# STM32F030x6 register map
File version: 1.0
Registers are 32-bit, read-write, reset 0x0 unless marked. A register's access mark holds for its fields unless they carry their own. Offsets are from the block's base; [hi:lo] are bit positions; {n}, {i} and the like mark numbered series.

## PWR — Power Control
Base 0x40007000
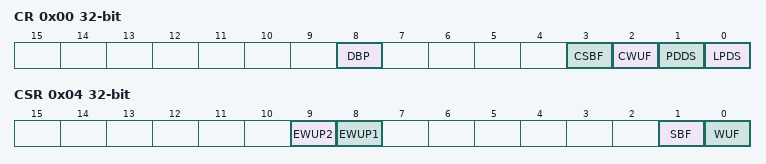
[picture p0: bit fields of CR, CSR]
0x00 CR — PWR power control register
  [8] DBP — Disable Backup Domain write protection
  [3] CSBF — Clear Standby Flag
  [2] CWUF — Clear Wakeup Flag
  [1] PDDS — Power Down Deepsleep
  [0] LPDS — Low-power Deepsleep
    0=MAIN (Voltage Regulator in main mode during deepsleep mode); 1=LOW_POWER (Voltage Regulator in low-power mode during deepsleep mode)
0x04 CSR — PWR power control/status register
  [9] EWUP2 — Enable WKUP pin 2
  [8] EWUP1 — Enable WKUP pin 1
  [1] SBF — Standby Flag
  [0] WUF — Wakeup Flag

## SYSCFG — SysTem Configuration
Base 0x40010000
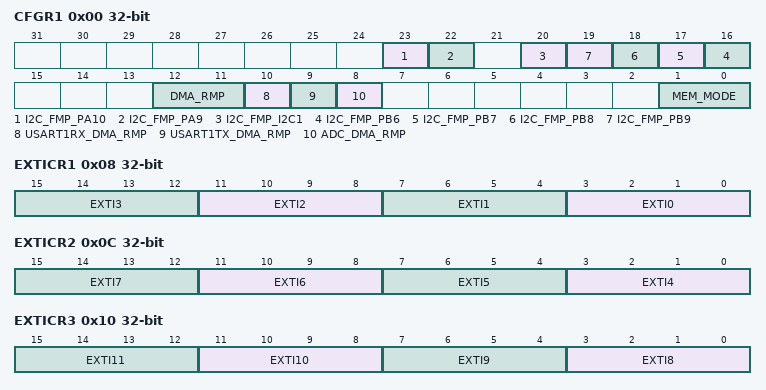
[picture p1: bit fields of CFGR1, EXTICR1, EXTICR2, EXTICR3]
0x00 CFGR1 — SYSCFG configuration register 1
  [23] I2C_FMP_PA10 — Enable Fast Mode Plus on PA10
  [22] I2C_FMP_PA9 — Enable Fast Mode Plus on PA9
  [20] I2C_FMP_I2C1 — Enable Fast Mode Plus on PB10, PB11, PF6 and PF7
  [n+10] I2C_FMP_PB{n} (n=6..9) — I2C PB{n} Fast mode plus
  [12:11] DMA_RMP — DMA remap mask
  [10] USART1RX_DMA_RMP — USART1 RX DMA remap
  [9] USART1TX_DMA_RMP — USART1 TX DMA remap
  [8] ADC_DMA_RMP — ADC DMA remap
    0=CH1 (ADC DMA request mapped on DMA channel 1U); 1=CH2 (ADC DMA request mapped on DMA channel 2U)
  [1:0] MEM_MODE — SYSCFG_Memory Remap Config
    0=FLASH (Main Flash memory mapped at 0x00000000); 1=SYSTEMFLASH (System Flash memory mapped at 0x00000000); 3=SRAM (Embedded SRAM mapped at 0x00000000)
0x08 EXTICR1 — SYSCFG external interrupt configuration register
  [4n+3:4n] EXTI{n} (n=0..3) — EXTI {n} configuration
0x0C EXTICR2 — SYSCFG external interrupt configuration register
  [4n-13:4n-16] EXTI{n} (n=4..7) — EXTI {n} configuration
0x10 EXTICR3 — SYSCFG external interrupt configuration register
  [4n-29:4n-32] EXTI{n} (n=8..11) — EXTI {n} configuration
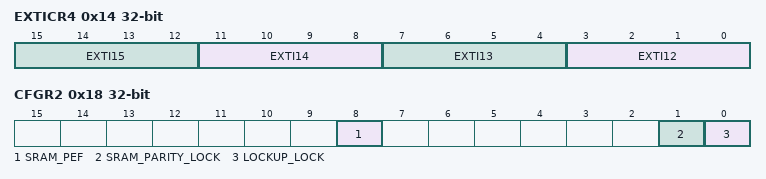
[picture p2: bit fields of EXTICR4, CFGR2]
0x14 EXTICR4 — SYSCFG external interrupt configuration register
  [4n-45:4n-48] EXTI{n} (n=12..15) — EXTI {n} configuration
0x18 CFGR2 — SYSCFG configuration register 2
  [8] SRAM_PEF — SRAM Parity error flag
  [1] SRAM_PARITY_LOCK — Enables and locks the SRAM_PARITY error signal with Break Input of TIMER1
  [0] LOCKUP_LOCK — Enables and locks the LOCKUP (Hardfault) output of CortexM0 with Break Input of TIMER1

## EXTI — External Interrupt/Event Controller
Base 0x40010400
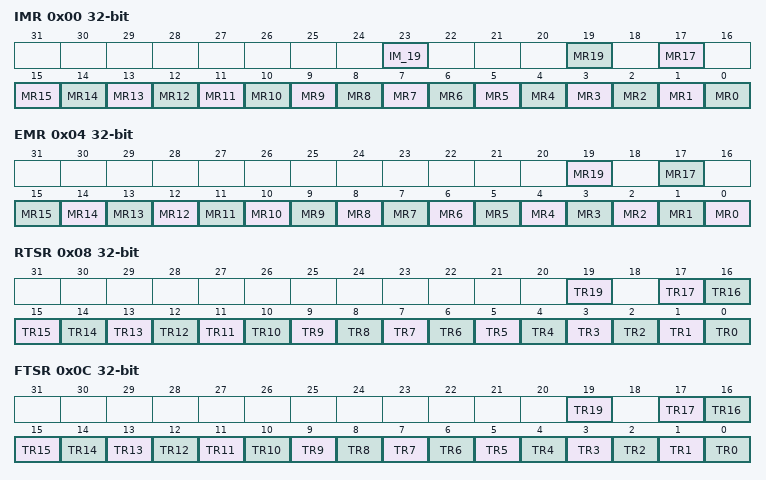
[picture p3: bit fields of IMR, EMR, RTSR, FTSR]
0x00 IMR — EXTI Interrupt mask register
  [23] IM_19 — Interrupt Mask All
  [19] MR19 — Interrupt Mask on line 19
  [17] MR17 — Interrupt Mask on line 17
  [n] MR{n} (n=0..15) — Interrupt Mask on line {n}
0x04 EMR — EXTI Event mask register
  [19] MR19 — Event Mask on line 19
  [17] MR17 — Event Mask on line 17
  [n] MR{n} (n=0..15) — Event Mask on line {n}
0x08 RTSR — EXTI Rising trigger selection register
  [19] TR19 — Rising trigger event configuration bit of line 19
  [n] TR{n} (n=0..17) — Rising trigger event configuration bit of line {n}
0x0C FTSR — EXTI Falling trigger selection register
  [19] TR19 — Falling trigger event configuration bit of line 19
  [n] TR{n} (n=0..17) — Falling trigger event configuration bit of line {n}
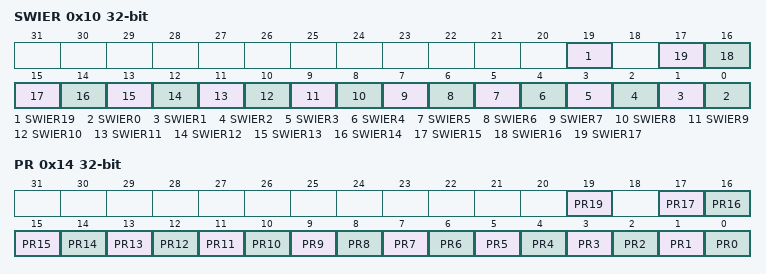
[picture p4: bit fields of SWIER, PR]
0x10 SWIER — EXTI Software interrupt event register
  [19] SWIER19 — Software Interrupt on line 19
  [n] SWIER{n} (n=0..17) — Software Interrupt on line {n}
0x14 PR — EXTI Pending register
  [19] PR19 — Pending bit 19
  [n] PR{n} (n=0..17) — Pending bit {n}

## ADC
Base 0x40012708
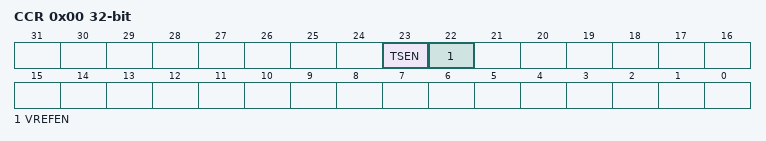
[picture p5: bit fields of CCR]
0x00 CCR — ADC common configuration register
  [23] TSEN — ADC internal path to temperature sensor enable
  [22] VREFEN — ADC internal path to VrefInt enable

## SPI1 — Serial Peripheral Interface
Base 0x40013000
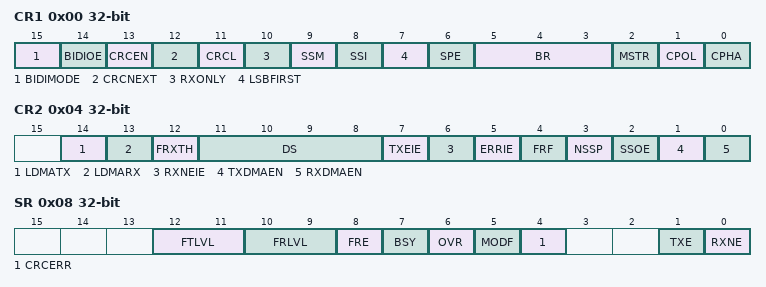
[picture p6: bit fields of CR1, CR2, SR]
0x00 CR1 — SPI Control register 1 (not used in I2S mode)
  [15] BIDIMODE — Bidirectional data mode enable
  [14] BIDIOE — Output enable in bidirectional mode
  [13] CRCEN — Hardware CRC calculation enable
  [12] CRCNEXT — Transmit CRC next
  [11] CRCL — CRC Length
    0=CRC_8BIT (8-bit CRC length); 1=CRC_16BIT (16-bit CRC length)
  [10] RXONLY — Receive only
  [9] SSM — Software slave management
  [8] SSI — Internal slave select
  [7] LSBFIRST — Frame Format
    1=LSB_FIRST (Data is transmitted/received with the LSB first); 0=MSB_FIRST (Data is transmitted/received with the MSB first)
  [6] SPE — SPI Enable
  [5:3] BR — BR[2:0] bits (Baud Rate Control)
    0=DIV2 (BaudRate control equal to fPCLK/2); 1=DIV4 (BaudRate control equal to fPCLK/4); 2=DIV8 (BaudRate control equal to fPCLK/8); 3=DIV16 (BaudRate control equal to fPCLK/16); 4=DIV32 (BaudRate control equal to fPCLK/32); 5=DIV64 (BaudRate control equal to fPCLK/64); 6=DIV128 (BaudRate control equal to fPCLK/128); 7=DIV256 (BaudRate control equal to fPCLK/256)
  [2] MSTR — Master Selection
  [1] CPOL — Clock Polarity
    0=LOW (Clock to 0 when idle); 1=HIGH (Clock to 1 when idle)
  [0] CPHA — Clock Phase
    0=PHASE_1EDGE (First clock transition is the first data capture edge); 1=PHASE_2EDGE (Second clock transition is the first data capture edge)
0x04 CR2 — SPI Control register 2
  [14] LDMATX — Last DMA transfer for transmission
  [13] LDMARX — Last DMA transfer for reception
  [12] FRXTH — FIFO reception Threshold
    0=HALF (RXNE event is generated if FIFO level is greater than or equal to 1/2 (16-bit)); 1=QUARTER (RXNE event is generated if FIFO level is greater than or equal to 1/4 (8-bit))
  [11:8] DS — DS[3:0] Data Size
    {v}=DATAWIDTH_{v+1}BIT (Data length for SPI transfer: {v+1} bits) (v=3..15)
  [7] TXEIE — Tx buffer Empty Interrupt Enable
  [6] RXNEIE — RX buffer Not Empty Interrupt Enable
  [5] ERRIE — Error Interrupt Enable
  [4] FRF — Frame Format Enable
    0=MOTOROLA (Motorola mode. Used as default value); 1=TI (TI mode)
  [3] NSSP — NSS pulse management Enable
  [2] SSOE — SS Output Enable
  [1] TXDMAEN — Tx Buffer DMA Enable
  [0] RXDMAEN — Rx Buffer DMA Enable
0x08 SR — SPI Status register
  [12:11] FTLVL — FIFO Transmission Level
    0=EMPTY (FIFO transmission empty); 1=QUARTER_FULL (FIFO transmission 1/4); 2=HALF_FULL (FIFO transmission 1/2); 3=FULL (FIFO transmission full)
  [10:9] FRLVL — FIFO Reception Level
    0=EMPTY (FIFO reception empty); 1=QUARTER_FULL (FIFO reception 1/4); 2=HALF_FULL (FIFO reception 1/2); 3=FULL (FIFO reception full)
  [8] FRE — TI frame format error
  [7] BSY — Busy flag
  [6] OVR — Overrun flag
  [5] MODF — Mode fault
  [4] CRCERR — CRC Error flag
  [1] TXE — Transmit buffer Empty
  [0] RXNE — Receive buffer Not Empty
0x0C DR — SPI data register
  [31:0] DR — Data Register
0x10 CRCPR — SPI CRC polynomial register (not used in I2S mode)
  [31:0] CRCPOLY — CRC polynomial register
0x14 RXCRCR — SPI Rx CRC register (not used in I2S mode)
  [31:0] RXCRC
0x18 TXCRCR — SPI Tx CRC register (not used in I2S mode)
  [31:0] TXCRC
0x1C I2SCFGR — SPI_I2S configuration register
  [11] I2SMOD — Keep for compatibility
